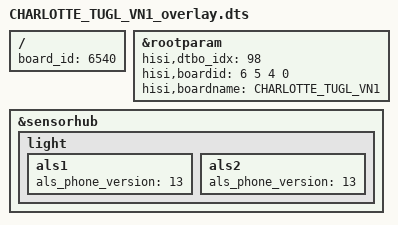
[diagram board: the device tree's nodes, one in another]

/**
 * Copyright (C) 2014 Hisilicon Ltd.
 *
 *  This program is free software; you can redistribute it and/or modify
 *  it under the terms of the GNU General Public License version 2 as
 *  publishhed by the Free Software Foundation.
 */

/dts-v1/;
/plugin/;
/include/ "CHARLOTTE_TUGL_V4_overlay.dtsi"

/ {
        board_id = <6540>;
};

&rootparam {
        hisi,dtbo_idx = <98>;
    hisi,boardid = <6 5 4 0>;
    hisi,boardname = "CHARLOTTE_TUGL_VN1";
};


&sensorhub {
	light{
		als1{
			als_phone_version = <13>;
		};
		als2{
			als_phone_version = <13>;
		};
	};
};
